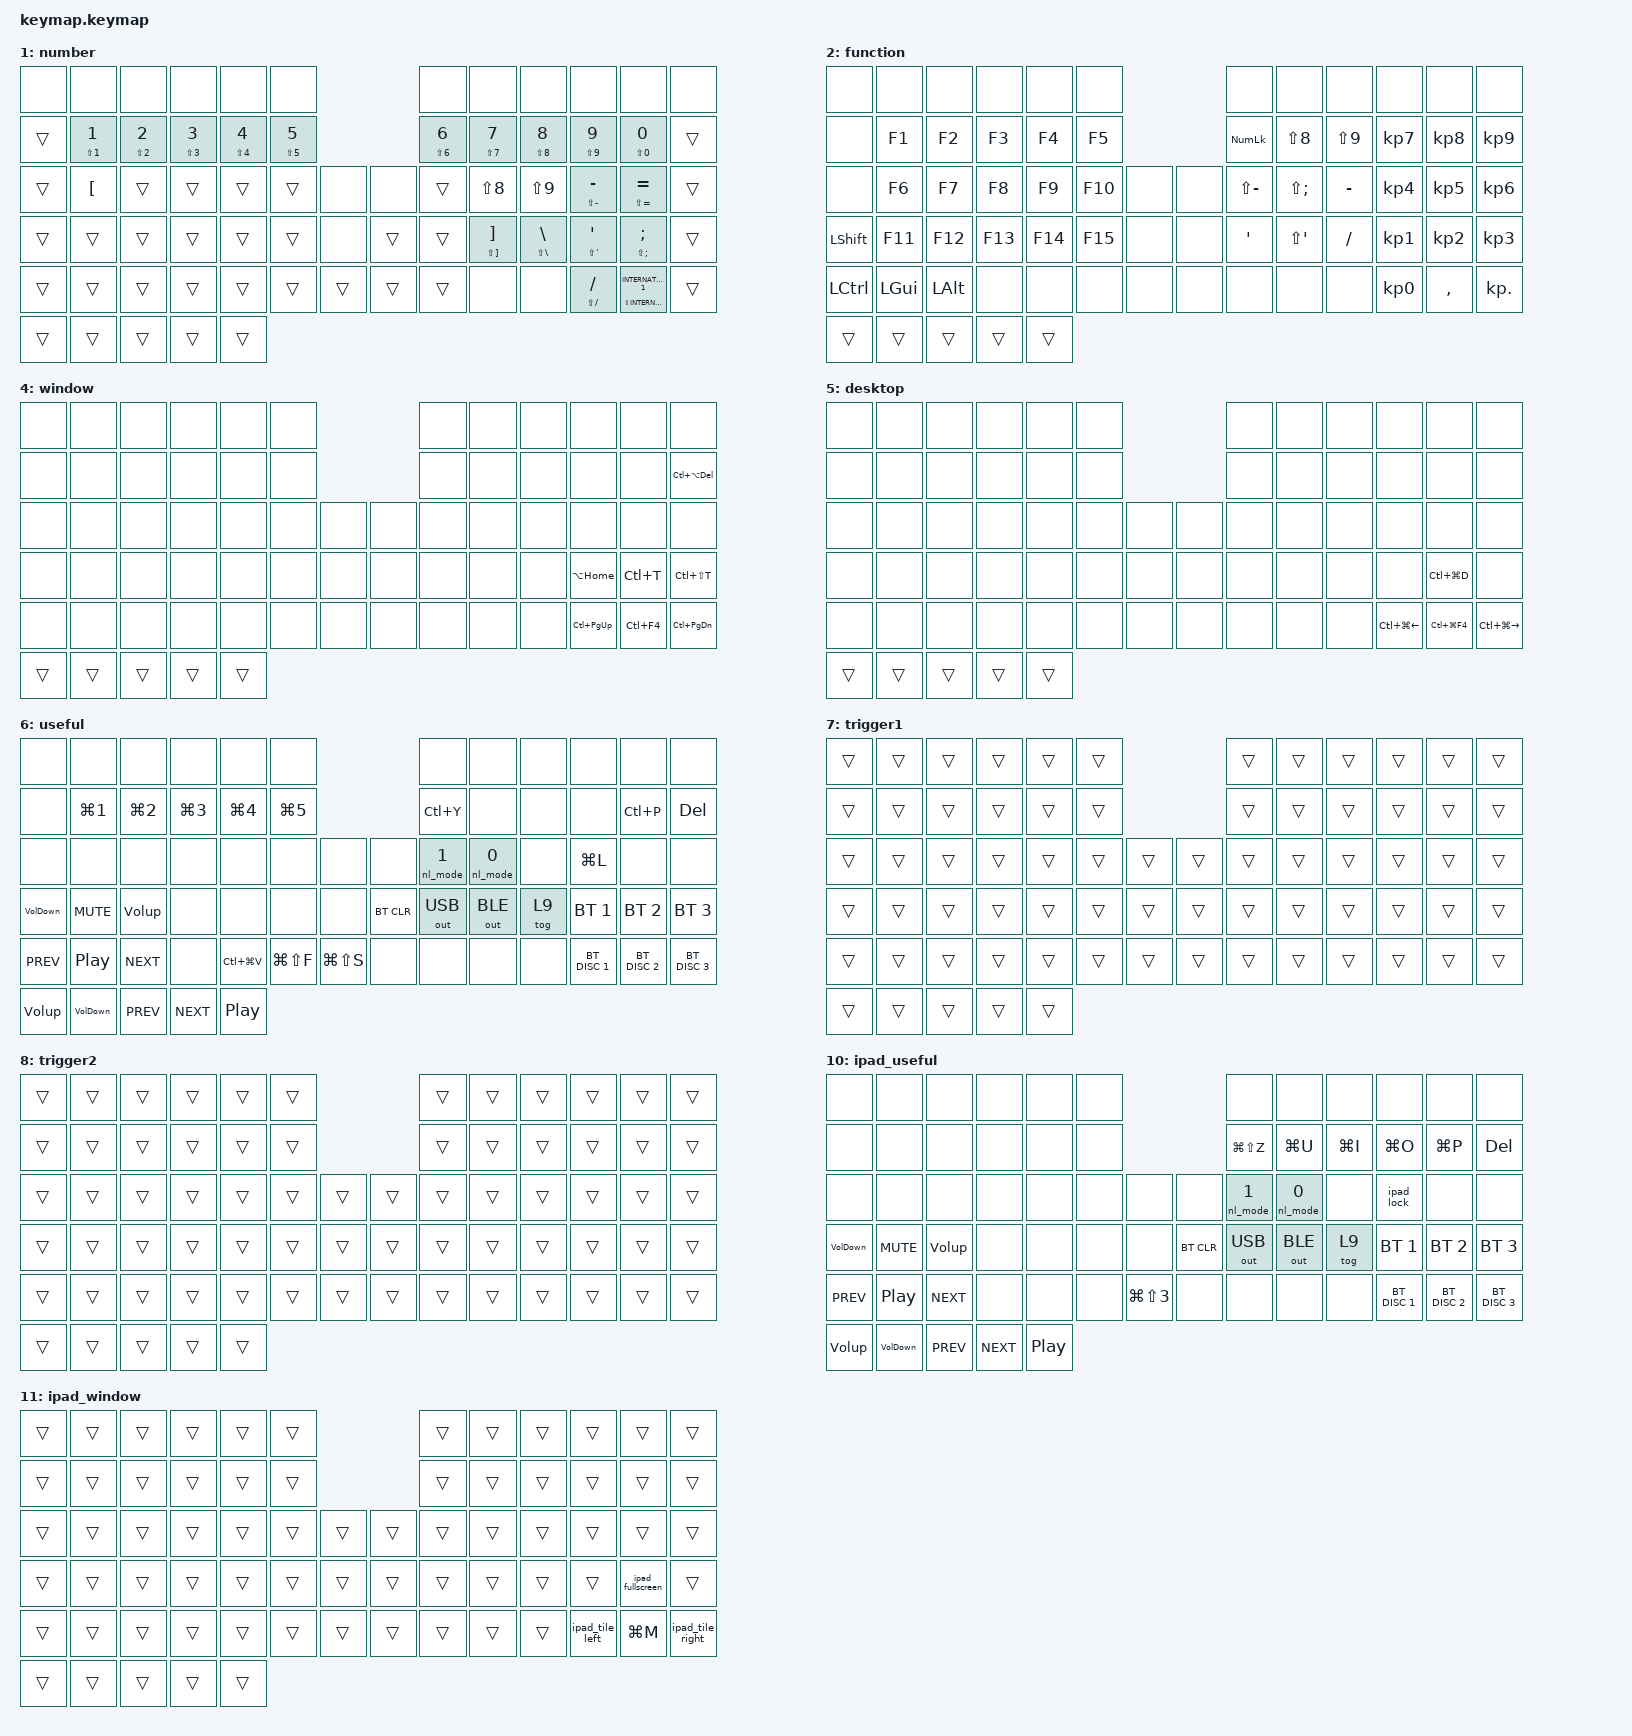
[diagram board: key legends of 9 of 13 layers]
#include <input/processors.dtsi>
#include <behaviors/nemu_link.dtsi>
#include <behaviors.dtsi>
#include <dt-bindings/zmk/bt.h>
#include <dt-bindings/zmk/keys.h>
#include <dt-bindings/zmk/outputs.h>
#include <dt-bindings/zmk/pointing.h>

/ {
    /*
     * nemu-link: hold-to-switch fallback ("chord").
     * Works on every half on its own (no dongle needed), e.g. to get back
     * from the 2.4GHz dongle to BLE. Hold both keys of the half:
     *   BLE -> 2.4GHz : 1.5 s,  2.4GHz -> BLE : 2.5 s
     * source-0 = left half (peripheral ID 0), source-1 = right half (ID 1).
     * The numbers are global key positions of this keymap:
     *   left : 12 (Esc) + 24 (Tab)
     *   right: 63 (Left arrow) + 65 (Right arrow)
     */

    nemu_link {
        compatible = "sekigon,nemu-link";
        source-0-switch-positions = <12 24>;
        source-1-switch-positions = <63 65>;
    };

    combos {
        compatible = "zmk,combos";

        MO4 {
            bindings = <&mo 4>;
            key-positions = <52 54>;
            timeout-ms = <200>;
            layers = <0>;
        };

        MO5 {
            bindings = <&mo 5>;
            key-positions = <52 53>;
            timeout-ms = <200>;
            layers = <0>;
        };

        sheetdel {
            bindings = <&HDS>;
            key-positions = <54 64>;
            timeout-ms = <50>;
            layers = <0>;
        };

        sheetadd {
            bindings = <&kp LS(F11)>;
            key-positions = <54 50>;
            timeout-ms = <50>;
            layers = <0>;
        };

        rowdel {
            bindings = <&kp LC(MINUS)>;
            key-positions = <54 35>;
            timeout-ms = <400>;
            layers = <0>;
        };

        rowadd {
            bindings = <&kp LS(LC(SEMI))>;
            key-positions = <54 36>;
            timeout-ms = <400>;
            layers = <0>;
        };

        selectdisplay {
            bindings = <&kp LA(SEMICOLON)>;
            key-positions = <54 49>;
            layers = <0>;
            timeout-ms = <400>;
        };

        ipad_window_combo {
            bindings = <&mo 11>;
            key-positions = <52 54>;
            timeout-ms = <200>;
            layers = <9>;
        };

        dispreset {
            bindings = <&kp LS(LC(LG(B)))>;
            key-positions = <12 23>;
        };
    };

    macros {
        HDS: HDS {
            compatible = "zmk,behavior-macro";
            #binding-cells = <0>;
            bindings = <&kp LEFT_ALT &kp H &kp D &kp S>;
            label = "HDS";
        };

        Volup: VolUPH {
            compatible = "zmk,behavior-macro";
            #binding-cells = <0>;
            bindings = <&kp C_VOLUME_UP &kp C_VOLUME_UP &kp C_VOLUME_UP>;
            label = "VOLUPH";
        };

        VolDown: VolDown {
            compatible = "zmk,behavior-macro";
            #binding-cells = <0>;
            bindings = <&kp C_VOLUME_DOWN &kp C_VOLUME_DOWN &kp C_VOLUME_DOWN>;
            label = "VOLDOWN";
        };

        ipad_tile_left: ipad_tile_left {
            compatible = "zmk,behavior-macro";
            #binding-cells = <0>;
            bindings =
                <&macro_press>,
                <&kp GLOBE &kp LCTRL>,
                <&macro_tap>,
                <&kp LEFT_ARROW>,
                <&macro_release>,
                <&kp LCTRL &kp GLOBE>;

            label = "IPAD_TILE_L";
        };

        ipad_tile_right: ipad_tile_right {
            compatible = "zmk,behavior-macro";
            #binding-cells = <0>;
            bindings =
                <&macro_press>,
                <&kp GLOBE &kp LCTRL>,
                <&macro_tap>,
                <&kp RIGHT_ARROW>,
                <&macro_release>,
                <&kp LCTRL &kp GLOBE>;

            label = "IPAD_TILE_R";
        };

        ipad_fullscreen: ipad_fullscreen {
            compatible = "zmk,behavior-macro";
            #binding-cells = <0>;
            bindings =
                <&macro_press>,
                <&kp GLOBE>,
                <&macro_tap>,
                <&kp F>,
                <&macro_release>,
                <&kp GLOBE>;

            label = "IPAD_FULL";
        };

        ipad_lock: ipad_lock {
            compatible = "zmk,behavior-macro";
            #binding-cells = <0>;
            bindings =
                <&macro_press>,
                <&kp TAB>,
                <&macro_tap>,
                <&kp L>,
                <&macro_release>,
                <&kp TAB>;

            label = "IPAD_LOCK";
        };

        ipad_applib: ipad_applib {
            compatible = "zmk,behavior-macro";
            #binding-cells = <0>;
            bindings =
                <&macro_press>,
                <&kp GLOBE &kp LSHFT>,
                <&macro_tap>,
                <&kp A>,
                <&macro_release>,
                <&kp LSHFT &kp GLOBE>;

            label = "IPAD_APPLIB";
        };

        ipad_siri: ipad_siri {
            compatible = "zmk,behavior-macro";
            #binding-cells = <0>;
            bindings =
                <&macro_press>,
                <&kp GLOBE>,
                <&macro_tap>,
                <&kp S>,
                <&macro_release>,
                <&kp GLOBE>;

            label = "IPAD_SIRI";
        };

        zoom_up: zoom_up {
            compatible = "zmk,behavior-macro";
            #binding-cells = <0>;
            bindings =
                <&macro_press>,
                <&kp LCTRL>,
                <&macro_press>,
                <&msc MOVE_Y(170)>,
                <&macro_pause_for_release>,
                <&macro_release>,
                <&msc MOVE_Y(170)>,
                <&macro_release>,
                <&kp LCTRL>;

            label = "ZOOM_UP";
        };

        zoom_down: zoom_down {
            compatible = "zmk,behavior-macro";
            #binding-cells = <0>;
            bindings =
                <&macro_press>,
                <&kp LCTRL>,
                <&macro_press>,
                <&msc (MOVE_Y(-170))>,
                <&macro_pause_for_release>,
                <&macro_release>,
                <&msc (MOVE_Y(-170))>,
                <&macro_release>,
                <&kp LCTRL>;

            label = "ZOOM_DOWN";
        };
    };

    behaviors {
        HoT: HoT {
            compatible = "zmk,behavior-hold-tap";
            label = "HOT";
            bindings = <&kp>, <&kp>;

            #binding-cells = <2>;
            tapping-term-ms = <200>;
            flavor = "tap-preferred";
        };

        alt_a_stab: alt_a_stab {
            compatible = "zmk,behavior-mod-morph";
            #binding-cells = <0>;
            bindings = <&kp A>, <&kp LS(TAB)>;

            mods = <(MOD_LALT)>;
            keep-mods = <(MOD_LALT)>;
        };
    };

    keymap {
        compatible = "zmk,keymap";

        layer_0 {
            bindings = <
&none             &none                &none                &none             &none         &none                                  &none        &none  &none      &none     &none           &none
&kp ESCAPE        &kp Q                &kp W                &kp E             &kp R         &kp T                                  &kp Y        &kp U  &kp I      &kp O     &kp P           &kp BACKSPACE
&kp TAB           &alt_a_stab          &kp S                &kp D             &kp F         &kp G  &none        &none              &kp H        &kp J  &kp K      &kp L     &kp MINUS       &none
&kp LSHFT         &kp Z                &kp X                &kp C             &kp V         &kp B  &none        &kp LG(LA(SPACE))  &kp N        &kp M  &kp COMMA  &kp DOT   &kp UP_ARROW    &kp SLASH
&kp LCTRL         &kp LEFT_GUI         &kp LEFT_ALT         &kp LS(LG(F23))   &lt 1 SPACE   &mo 7  &lt 2 LANG2  &kp LANG1          &lt 6 ENTER  &none  &none      &kp LEFT  &kp DOWN_ARROW  &kp RIGHT
&msc MOVE_Y(340)  &msc (MOVE_Y(-340))  &msc (MOVE_X(-170))  &msc MOVE_X(170)  &kp LC(HOME)
            >;
        };

        number {
            bindings = <
&none   &none                       &none                       &none                       &none                       &none                                       &none                       &none                       &none                         &none                               &none                                     &none
&trans  &HoT LS(NUMBER_1) NUMBER_1  &HoT LS(NUMBER_2) NUMBER_2  &HoT LS(NUMBER_3) NUMBER_3  &HoT LS(NUMBER_4) NUMBER_4  &HoT LS(NUMBER_5) NUMBER_5                  &HoT LS(NUMBER_6) NUMBER_6  &HoT LS(NUMBER_7) NUMBER_7  &HoT LS(NUMBER_8) NUMBER_8    &HoT LS(NUMBER_9) NUMBER_9          &HoT LS(NUMBER_0) NUMBER_0                &trans
&trans  &kp LEFT_BRACKET            &trans                      &trans                      &trans                      &trans                      &none   &none   &trans                      &kp LS(NUMBER_8)            &kp LS(NUMBER_9)              &HoT LS(MINUS) MINUS                &HoT LS(EQUAL) EQUAL                      &trans
&trans  &trans                      &trans                      &trans                      &trans                      &trans                      &none   &trans  &trans                      &HoT LS(RBKT) RBKT          &HoT LS(BACKSLASH) BACKSLASH  &HoT LS(SINGLE_QUOTE) SINGLE_QUOTE  &HoT LS(SEMICOLON) SEMICOLON              &trans
&trans  &trans                      &trans                      &trans                      &trans                      &trans                      &trans  &trans  &trans                      &none                       &none                         &HoT LS(SLASH) SLASH                &HoT LS(INTERNATIONAL_1) INTERNATIONAL_1  &trans
&trans  &trans                      &trans                      &trans                      &trans
            >;
        };

        function {
            bindings = <
&none           &none         &none         &none    &none    &none                  &none             &none              &none             &none            &none            &none
&none           &kp F1        &kp F2        &kp F3   &kp F4   &kp F5                 &kp KP_NUMLOCK    &kp LS(N8)         &kp LS(NUMBER_9)  &kp KP_NUMBER_7  &kp KP_NUMBER_8  &kp KP_NUMBER_9
&none           &kp F6        &kp F7        &kp F8   &kp F9   &kp F10  &none  &none  &kp LS(MINUS)     &kp LS(SEMICOLON)  &kp MINUS         &kp KP_NUMBER_4  &kp KP_NUMBER_5  &kp KP_NUMBER_6
&kp LEFT_SHIFT  &kp F11       &kp F12       &kp F13  &kp F14  &kp F15  &none  &none  &kp SINGLE_QUOTE  &kp LS(APOS)       &kp SLASH         &kp KP_NUMBER_1  &kp KP_NUMBER_2  &kp KP_NUMBER_3
&kp LCTRL       &kp LEFT_GUI  &kp LEFT_ALT  &none    &none    &none    &none  &none  &none             &none              &none             &kp KP_NUMBER_0  &kp COMMA        &kp KP_DOT
&trans          &trans        &trans        &trans   &trans
            >;
        };

        mouse {
            bindings = <
&none           &none         &none               &none                &none             &none                             &none    &none      &none      &none  &none  &none
&none           &none         &kp F2              &msc MOVE_Y(170)     &kp LA(F4)        &none                             &none    &none      &mkp MCLK  &none  &none  &kp DELETE
&kp LC(TAB)     &none         &msc (MOVE_X(-85))  &msc (MOVE_Y(-170))  &msc MOVE_X(85)   &none  &none  &none               &none    &mkp LCLK  &mkp RCLK  &none  &none  &none
&kp LEFT_SHIFT  &none         &none               &none                &none             &none  &none  &none               &none    &mkp MB4   &mkp MB5   &none  &none  &none
&kp LCTRL       &kp LEFT_GUI  &kp LEFT_ALT        &none                &none             &none  &none  &HoT LC(HOME) HOME  &kp END  &none      &none      &none  &none  &none
&zoom_up        &zoom_down    &none               &none                &kp LC(NUMBER_0)
            >;
        };

        window {
            bindings = <
&none   &none   &none   &none   &none   &none                &none  &none  &none  &none            &none       &none
&none   &none   &none   &none   &none   &none                &none  &none  &none  &none            &none       &kp LC(LA(DELETE))
&none   &none   &none   &none   &none   &none  &none  &none  &none  &none  &none  &none            &none       &none
&none   &none   &none   &none   &none   &none  &none  &none  &none  &none  &none  &kp LA(HOME)     &kp LC(T)   &kp LC(LS(T))
&none   &none   &none   &none   &none   &none  &none  &none  &none  &none  &none  &kp LC(PAGE_UP)  &kp LC(F4)  &kp LC(PAGE_DOWN)
&trans  &trans  &trans  &trans  &trans
            >;
        };

        desktop {
            bindings = <
&none   &none   &none   &none   &none   &none                &none  &none  &none  &none             &none           &none
&none   &none   &none   &none   &none   &none                &none  &none  &none  &none             &none           &none
&none   &none   &none   &none   &none   &none  &none  &none  &none  &none  &none  &none             &none           &none
&none   &none   &none   &none   &none   &none  &none  &none  &none  &none  &none  &none             &kp LC(LG(D))   &none
&none   &none   &none   &none   &none   &none  &none  &none  &none  &none  &none  &kp LC(LG(LEFT))  &kp LC(LG(F4))  &kp LC(LG(RIGHT))
&trans  &trans  &trans  &trans  &trans
            >;
        };

        useful {
            bindings = <
&none       &none             &none             &none             &none             &none                                        &none         &none         &none   &none          &none          &none
&none       &kp LG(NUMBER_1)  &kp LG(NUMBER_2)  &kp LG(NUMBER_3)  &kp LG(NUMBER_4)  &kp LG(NUMBER_5)                             &kp LC(Y)     &none         &none   &none          &kp LC(P)      &kp DELETE
&none       &none             &none             &none             &none             &none             &none          &none       &nl_mode 1    &nl_mode 0    &none   &kp LG(L)      &none          &none
&VolDown    &kp C_MUTE        &Volup            &none             &none             &none             &none          &bt BT_CLR  &out OUT_USB  &out OUT_BLE  &tog 9  &bt BT_SEL 1   &bt BT_SEL 2   &bt BT_SEL 3
&kp C_PREV  &kp C_PLAY_PAUSE  &kp C_NEXT        &none             &kp LC(LG(V))     &kp LG(LS(F))     &kp LG(LS(S))  &none       &none         &none         &none   &bt BT_DISC 1  &bt BT_DISC 2  &bt BT_DISC 3
&Volup      &VolDown          &kp C_PREV        &kp C_NEXT        &kp C_PLAY_PAUSE
            >;
        };

        trigger1 {
            bindings = <
&trans  &trans  &trans  &trans  &trans  &trans                  &trans  &trans  &trans  &trans  &trans  &trans
&trans  &trans  &trans  &trans  &trans  &trans                  &trans  &trans  &trans  &trans  &trans  &trans
&trans  &trans  &trans  &trans  &trans  &trans  &trans  &trans  &trans  &trans  &trans  &trans  &trans  &trans
&trans  &trans  &trans  &trans  &trans  &trans  &trans  &trans  &trans  &trans  &trans  &trans  &trans  &trans
&trans  &trans  &trans  &trans  &trans  &trans  &trans  &trans  &trans  &trans  &trans  &trans  &trans  &trans
&trans  &trans  &trans  &trans  &trans
            >;
        };

        trigger2 {
            bindings = <
&trans  &trans  &trans  &trans  &trans  &trans                  &trans  &trans  &trans  &trans  &trans  &trans
&trans  &trans  &trans  &trans  &trans  &trans                  &trans  &trans  &trans  &trans  &trans  &trans
&trans  &trans  &trans  &trans  &trans  &trans  &trans  &trans  &trans  &trans  &trans  &trans  &trans  &trans
&trans  &trans  &trans  &trans  &trans  &trans  &trans  &trans  &trans  &trans  &trans  &trans  &trans  &trans
&trans  &trans  &trans  &trans  &trans  &trans  &trans  &trans  &trans  &trans  &trans  &trans  &trans  &trans
&trans  &trans  &trans  &trans  &trans
            >;
        };

        ipad_base {
            bindings = <
&trans           &trans              &trans              &trans           &trans         &trans                             &trans        &trans  &trans  &trans  &trans  &trans
&trans           &trans              &trans              &trans           &trans         &trans                             &trans        &trans  &trans  &trans  &trans  &trans
&trans           &trans              &trans              &trans           &trans         &trans  &trans       &trans        &trans        &trans  &trans  &trans  &trans  &trans
&trans           &trans              &trans              &trans           &trans         &trans  &none        &ipad_applib  &trans        &trans  &trans  &trans  &trans  &trans
&kp LEFT_GUI     &kp GLOBE           &trans              &ipad_siri       &trans         &trans  &lt 2 LANG2  &kp LANG1     &lt 10 ENTER  &trans  &trans  &trans  &trans  &trans
&msc MOVE_Y(40)  &msc (MOVE_Y(-40))  &msc (MOVE_X(-40))  &msc MOVE_X(40)  &kp LG(SPACE)
            >;
        };

        ipad_useful {
            bindings = <
&none       &none             &none       &none       &none             &none                                    &none          &none         &none      &none          &none          &none
&none       &none             &none       &none       &none             &none                                    &kp LG(LS(Z))  &kp LG(U)     &kp LG(I)  &kp LG(O)      &kp LG(P)      &kp DELETE
&none       &none             &none       &none       &none             &none  &none                 &none       &nl_mode 1     &nl_mode 0    &none      &ipad_lock     &none          &none
&VolDown    &kp C_MUTE        &Volup      &none       &none             &none  &none                 &bt BT_CLR  &out OUT_USB   &out OUT_BLE  &tog 9     &bt BT_SEL 1   &bt BT_SEL 2   &bt BT_SEL 3
&kp C_PREV  &kp C_PLAY_PAUSE  &kp C_NEXT  &none       &none             &none  &kp LG(LS(NUMBER_3))  &none       &none          &none         &none      &bt BT_DISC 1  &bt BT_DISC 2  &bt BT_DISC 3
&Volup      &VolDown          &kp C_PREV  &kp C_NEXT  &kp C_PLAY_PAUSE
            >;
        };

        ipad_window {
            bindings = <
&trans  &trans  &trans  &trans  &trans  &trans                  &trans  &trans  &trans  &trans           &trans            &trans
&trans  &trans  &trans  &trans  &trans  &trans                  &trans  &trans  &trans  &trans           &trans            &trans
&trans  &trans  &trans  &trans  &trans  &trans  &trans  &trans  &trans  &trans  &trans  &trans           &trans            &trans
&trans  &trans  &trans  &trans  &trans  &trans  &trans  &trans  &trans  &trans  &trans  &trans           &ipad_fullscreen  &trans
&trans  &trans  &trans  &trans  &trans  &trans  &trans  &trans  &trans  &trans  &trans  &ipad_tile_left  &kp LG(M)         &ipad_tile_right
&trans  &trans  &trans  &trans  &trans
            >;
        };

        ipad_mouse {
            bindings = <
&trans          &trans  &trans              &trans              &trans           &trans                  &trans  &trans                 &trans               &trans  &trans  &trans
&trans          &trans  &trans              &msc MOVE_Y(20)     &trans           &trans                  &trans  &trans                 &mkp MCLK            &trans  &trans  &kp DELETE
&kp LC(TAB)     &trans  &msc (MOVE_X(-20))  &msc (MOVE_Y(-20))  &msc MOVE_X(20)  &trans  &trans  &trans  &trans  &mkp LCLK              &mkp RCLK            &trans  &trans  &trans
&kp LEFT_SHIFT  &trans  &trans              &trans              &trans           &trans  &trans  &trans  &trans  &kp LG(RIGHT_BRACKET)  &kp LG(NON_US_HASH)  &trans  &trans  &trans
&trans          &trans  &trans              &trans              &trans           &trans  &trans  &trans  &trans  &trans                 &trans               &trans  &trans  &trans
&trans          &trans  &trans              &trans              &trans
            >;
        };
    };

    conditional_layers {
        compatible = "zmk,conditional-layers";

        AML1 {
            if-layers = <7>;
            then-layer = <3>;
        };

        AML2 {
            if-layers = <8>;
            then-layer = <3>;
        };

        AML3 {
            if-layers = <9 8>;
            then-layer = <12>;
        };

        AML4 {
            if-layers = <9 7>;
            then-layer = <12>;
        };
    };
};

#ifndef NEMU_LINK_DONGLE

/* keyboard halves only: the dongle gets its own listener in nemu-link-dongle.overlay */

&pointing_listener { input-processors = <&zip_xy_transform (INPUT_TRANSFORM_X_INVERT | INPUT_TRANSFORM_Y_INVERT) &zip_temp_layer 8 175>; };

#endif

&zip_temp_layer {
    require-prior-idle-ms = <400>;
    excluded-positions = <14 15 16 20 23 26 27 28 33 34 38 47 48 52 53 54 59 60 66 67 70>;
};
